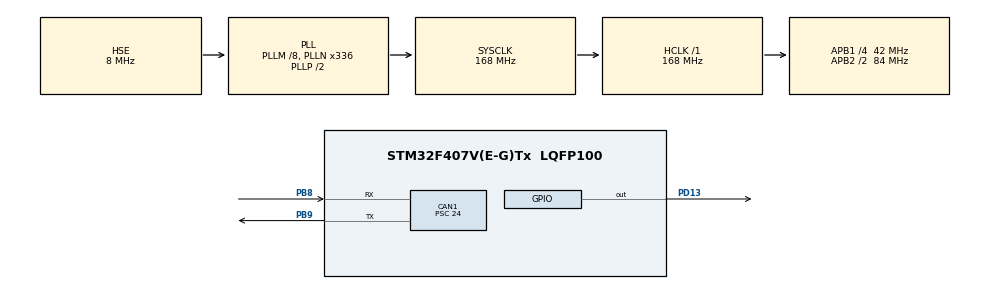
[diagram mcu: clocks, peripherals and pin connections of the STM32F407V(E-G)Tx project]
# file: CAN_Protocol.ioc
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CAN1.BS1=CAN_BS1_3TQ
CAN1.BS2=CAN_BS2_3TQ
CAN1.CalculateBaudRate=250000
CAN1.CalculateTimeBit=4000
CAN1.CalculateTimeQuantum=571.4285714285714
CAN1.Prescaler=24
Mcu.Family=STM32F4
Mcu.Name=STM32F407V(E-G)Tx
Mcu.Package=LQFP100
NVIC.PriorityGroup=NVIC_PRIORITYGROUP_0
PB8.Mode=CAN_Activate
PB8.Signal=CAN1_RX
PB9.Mode=CAN_Activate
PB9.Signal=CAN1_TX
PD13.Signal=GPIO_Output
PH0-OSC_IN.Mode=HSE-External-Oscillator
PH0-OSC_IN.Signal=RCC_OSC_IN
PH1-OSC_OUT.Mode=HSE-External-Oscillator
PH1-OSC_OUT.Signal=RCC_OSC_OUT
ProjectManager.HeapSize=0x200
ProjectManager.StackSize=0x400
ProjectManager.TargetToolchain=STM32CubeIDE
RCC.48MHZClocksFreq_Value=48000000
RCC.AHBFreq_Value=168000000
RCC.APB1CLKDivider=RCC_HCLK_DIV4
RCC.APB1Freq_Value=42000000
RCC.APB1TimFreq_Value=84000000
RCC.APB2CLKDivider=RCC_HCLK_DIV2
RCC.APB2Freq_Value=84000000
RCC.APB2TimFreq_Value=168000000
RCC.CortexFreq_Value=168000000
RCC.HCLKFreq_Value=168000000
RCC.HSE_VALUE=8000000
RCC.HSI_VALUE=16000000
RCC.LSE_VALUE=32768
RCC.PLLM=8
RCC.PLLN=336
RCC.PLLQ=7
RCC.PLLSourceVirtual=RCC_PLLSOURCE_HSE
RCC.SYSCLKFreq_VALUE=168000000
RCC.SYSCLKSource=RCC_SYSCLKSOURCE_PLLCLK
RCC.VCOOutputFreq_Value=336000000
board=STM32F407G-DISC1

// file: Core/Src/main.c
/* USER CODE BEGIN Header */
/**
  ******************************************************************************
  * @file           : main.c
  * @brief          : Main program body
  ******************************************************************************
  * @attention
  *
  * Copyright (c) 2025 STMicroelectronics.
  * All rights reserved.
  *
  * This software is licensed under terms that can be found in the LICENSE file
  * in the root directory of this software component.
  * If no LICENSE file comes with this software, it is provided AS-IS.
  *
  ******************************************************************************
  */
/* USER CODE END Header */
#include "main.h"

CAN_HandleTypeDef hcan1;

void SystemClock_Config(void);
static void MX_GPIO_Init(void);
static void MX_CAN1_Init(void);

/* USER CODE BEGIN 0 */

CAN_TxHeaderTypeDef TxTransmitter;
CAN_RxHeaderTypeDef RxReceiver;

uint8_t Received_Data[8];
uint8_t Transmitted_Data[8];

uint32_t VericiBilgileri[5];

uint32_t TxMailbox;

uint8_t sayac=0;

void HAL_CAN_RxFifo0MsgPendingCallback(CAN_HandleTypeDef *hcan){

	HAL_CAN_GetRxMessage(hcan, CAN_RX_FIFO0, &RxReceiver, Received_Data);
	if(hcan==&hcan1){

		HAL_GPIO_WritePin(GPIOD, GPIO_PIN_13, 1);
	}

}

/* USER CODE END 0 */

int main(void)
{

  /* MCU Configuration--------------------------------------------------------*/

  /* Reset of all peripherals, Initializes the Flash interface and the Systick. */
  HAL_Init();

  /* Configure the system clock */
  SystemClock_Config();

  /* Initialize all configured peripherals */
  MX_GPIO_Init();
  MX_CAN1_Init();
  /* USER CODE BEGIN 2 */

  HAL_CAN_Start(&hcan1);

  HAL_CAN_ActivateNotification(&hcan1, CAN_IT_RX_FIFO0_MSG_PENDING);
  TxTransmitter.StdId = 0x75; // ID
  TxTransmitter.DLC = 8;     // Data Length
  TxTransmitter.RTR = CAN_RTR_DATA;
  TxTransmitter.IDE = CAN_ID_STD; // DATA Type (Standart or Extended)

  /* USER CODE END 2 */

  /* Infinite loop */
  while (1)
  {

    /* USER CODE BEGIN 3 */
	  HAL_Delay(50);   // VERİ GÖNDERME
	  sayac += 1;
	  if(sayac==255)
	  {
		  sayac=0;
	  }
		  Transmitted_Data[0]=125;
		  Transmitted_Data[1]=25;
		  Transmitted_Data[2]=32;
		  Transmitted_Data[3]=50;
		  Transmitted_Data[4]=sayac;
		  Transmitted_Data[5]=sayac;
		  Transmitted_Data[6]=sayac;
		  Transmitted_Data[7]=sayac;
		  HAL_CAN_AddTxMessage(&hcan1, &TxTransmitter, Transmitted_Data, &TxMailbox);

//	  HAL_CAN_GetRxMessage(&hcan1, CAN_RX_FIFO0, &RxReceiver, Received_Data);
//	  VericiBilgileri[0] = RxReceiver.StdId;
//	  VericiBilgileri[1] = RxReceiver.ExtId;
//	  VericiBilgileri[2] = RxReceiver.IDE; // Standart mı extend mi
//	  VericiBilgileri[3] = RxReceiver.RTR;
//	  VericiBilgileri[4] = RxReceiver.DLC; // Gelen verinin boyutu
  }
  /* USER CODE END 3 */
}

void SystemClock_Config(void)
{
  RCC_OscInitTypeDef RCC_OscInitStruct = {0};
  RCC_ClkInitTypeDef RCC_ClkInitStruct = {0};

  /** Configure the main internal regulator output voltage
  */
  __HAL_RCC_PWR_CLK_ENABLE();
  __HAL_PWR_VOLTAGESCALING_CONFIG(PWR_REGULATOR_VOLTAGE_SCALE1);

  /** Initializes the RCC Oscillators according to the specified parameters
  * in the RCC_OscInitTypeDef structure.
  */
  RCC_OscInitStruct.OscillatorType = RCC_OSCILLATORTYPE_HSE;
  RCC_OscInitStruct.HSEState = RCC_HSE_ON;
  RCC_OscInitStruct.PLL.PLLState = RCC_PLL_ON;
  RCC_OscInitStruct.PLL.PLLSource = RCC_PLLSOURCE_HSE;
  RCC_OscInitStruct.PLL.PLLM = 8;
  RCC_OscInitStruct.PLL.PLLN = 336;
  RCC_OscInitStruct.PLL.PLLP = RCC_PLLP_DIV2;
  RCC_OscInitStruct.PLL.PLLQ = 7;
  if (HAL_RCC_OscConfig(&RCC_OscInitStruct) != HAL_OK)
  {
    Error_Handler();
  }

  /** Initializes the CPU, AHB and APB buses clocks
  */
  RCC_ClkInitStruct.ClockType = RCC_CLOCKTYPE_HCLK|RCC_CLOCKTYPE_SYSCLK
                              |RCC_CLOCKTYPE_PCLK1|RCC_CLOCKTYPE_PCLK2;
  RCC_ClkInitStruct.SYSCLKSource = RCC_SYSCLKSOURCE_PLLCLK;
  RCC_ClkInitStruct.AHBCLKDivider = RCC_SYSCLK_DIV1;
  RCC_ClkInitStruct.APB1CLKDivider = RCC_HCLK_DIV4;
  RCC_ClkInitStruct.APB2CLKDivider = RCC_HCLK_DIV2;

  if (HAL_RCC_ClockConfig(&RCC_ClkInitStruct, FLASH_LATENCY_5) != HAL_OK)
  {
    Error_Handler();
  }
}

static void MX_CAN1_Init(void)
{

  hcan1.Instance = CAN1;
  hcan1.Init.Prescaler = 24;
  hcan1.Init.Mode = CAN_MODE_NORMAL;
  hcan1.Init.SyncJumpWidth = CAN_SJW_1TQ;
  hcan1.Init.TimeSeg1 = CAN_BS1_3TQ;
  hcan1.Init.TimeSeg2 = CAN_BS2_3TQ;
  hcan1.Init.TimeTriggeredMode = DISABLE;
  hcan1.Init.AutoBusOff = DISABLE;
  hcan1.Init.AutoWakeUp = DISABLE;
  hcan1.Init.AutoRetransmission = DISABLE;
  hcan1.Init.ReceiveFifoLocked = DISABLE;
  hcan1.Init.TransmitFifoPriority = DISABLE;
  if (HAL_CAN_Init(&hcan1) != HAL_OK)
  {
    Error_Handler();
  }
  /* USER CODE BEGIN CAN1_Init 2 */

  CAN_FilterTypeDef Gelen_Data_Filter;

  Gelen_Data_Filter.FilterActivation = CAN_FILTER_ENABLE;
  Gelen_Data_Filter.FilterBank = 13;
  Gelen_Data_Filter.FilterFIFOAssignment = CAN_FILTER_FIFO0; // Datayı okuyacağı yer

  Gelen_Data_Filter.FilterIdHigh= 0x75 <<5; //11 bit
  Gelen_Data_Filter.FilterIdLow = 0x0000;
  Gelen_Data_Filter.FilterMaskIdHigh = 0xFFFF<<5;
  Gelen_Data_Filter.FilterMaskIdLow = 0xFFFF;

  Gelen_Data_Filter.FilterMode = CAN_FILTERMODE_IDMASK;
  Gelen_Data_Filter.FilterScale = CAN_FILTERSCALE_32BIT;
  Gelen_Data_Filter.SlaveStartFilterBank =0;
  HAL_CAN_ConfigFilter(&hcan1, &Gelen_Data_Filter);

  /* USER CODE END CAN1_Init 2 */

}

static void MX_GPIO_Init(void)
{

  /* GPIO Ports Clock Enable */
  __HAL_RCC_GPIOH_CLK_ENABLE();
  __HAL_RCC_GPIOB_CLK_ENABLE();

}

void Error_Handler(void)
{
  __disable_irq();
  while (1)
  {
  }
}
